# sema_reva2_me55 register map
Registers are 32-bit, access not given, no defined reset value unless marked. A register's access mark holds for its fields unless they carry their own. Offsets are from the block's base; lines under a group give offsets from that group; [hi:lo] are bit positions; {n}, {i} and the like mark numbered series; 'fields as' and 'values as' point back to an identical list; <NAME> marks a mode.

## Memory map
0x4003E000 SEMA size 0x1000 — The Semaphore peripheral allows multiple cores in a system to cooperate when accessing shred resources. The peripheral contains eight semaphores that can be atomically set and cleared. It is left to the discretion of the software architect to decide how and when the semaphores are used and how they are allocated. Existing hardware does not have to be modified for this type of cooperative sharing, and the use of semaphores is exclusively within the software domain.

## SEMA — The Semaphore peripheral allows multiple cores in a system to cooperate when accessing shred resources. The peripheral contains eight semaphores that can be atomically set and cleared. It is left to the discretion of the software architect to decide how and when the semaphores are used and how they are allocated. Existing hardware does not have to be modified for this type of cooperative sharing, and the use of semaphores is exclusively within the software domain.
Base 0x4003E000
{0x0+4i} SEMAPHORES[{i}] (i=0..7) — Read to test and set, returns prior value. Write 0 to clear semaphore.
  [0] sema
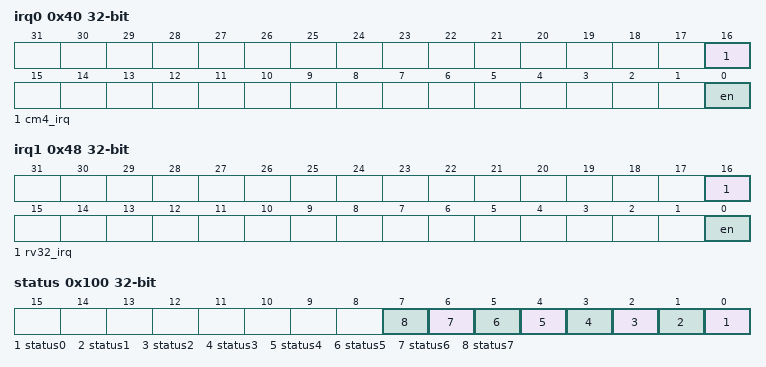
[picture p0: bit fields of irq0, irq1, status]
0x40 irq0 — Semaphore IRQ0 register.
  [16] cm4_irq, [0] en
0x44 mail0 — Semaphore Mailbox 0 register.
  [31:0] data
0x48 irq1 — Semaphore IRQ1 register.
  [16] rv32_irq, [0] en
0x4C mail1 — Semaphore Mailbox 1 register.
  [31:0] data
0x100 status — Semaphore status bits. 0 indicates the semaphore is free, 1 indicates taken.
  [n] status{n} (n=0..7)
